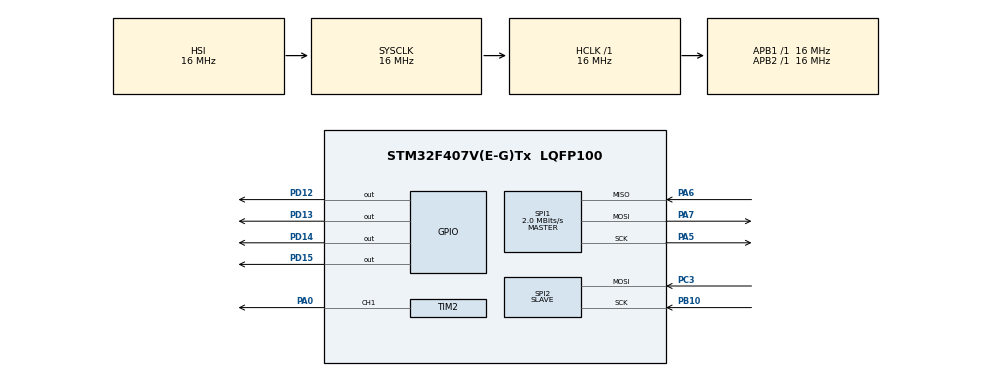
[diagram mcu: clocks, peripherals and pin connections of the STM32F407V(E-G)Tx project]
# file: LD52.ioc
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Mcu.Family=STM32F4
Mcu.Name=STM32F407V(E-G)Tx
Mcu.Package=LQFP100
NVIC.PriorityGroup=NVIC_PRIORITYGROUP_4
NVIC.SPI2_IRQn=true\:0\:0\:false\:false\:true\:true\:true\:true
NVIC.TIM2_IRQn=true\:0\:0\:false\:false\:true\:true\:true\:true
PA0-WKUP.Signal=S_TIM2_CH1_ETR
PA13.Mode=Trace_Asynchronous_SW
PA13.Signal=SYS_JTMS-SWDIO
PA14.Mode=Trace_Asynchronous_SW
PA14.Signal=SYS_JTCK-SWCLK
PA5.Mode=Full_Duplex_Master
PA5.Signal=SPI1_SCK
PA6.Mode=Full_Duplex_Master
PA6.Signal=SPI1_MISO
PA7.Mode=Full_Duplex_Master
PA7.Signal=SPI1_MOSI
PB10.Mode=RX_Only_Simplex_Unidirect_Slave
PB10.Signal=SPI2_SCK
PB3.Mode=Trace_Asynchronous_SW
PB3.Signal=SYS_JTDO-SWO
PC2.Signal=SPI2_MISO
PC3.Mode=RX_Only_Simplex_Unidirect_Slave
PC3.Signal=SPI2_MOSI
PD12.Signal=GPIO_Output
PD13.Signal=GPIO_Output
PD14.Signal=GPIO_Output
PD15.Signal=GPIO_Output
ProjectManager.HeapSize=0x200
ProjectManager.StackSize=0x400
ProjectManager.TargetToolchain=STM32CubeIDE
RCC.AHBFreq_Value=16000000
RCC.APB1Freq_Value=16000000
RCC.APB2Freq_Value=16000000
RCC.CortexFreq_Value=16000000
RCC.HSE_VALUE=25000000
RCC.HSI_VALUE=16000000
RCC.LSE_VALUE=32768
RCC.SYSCLKFreq_VALUE=16000000
RCC.VCOOutputFreq_Value=192000000
SH.S_TIM2_CH1_ETR.0=TIM2_CH1,PWM Generation1 CH1
SPI1.BaudRatePrescaler=SPI_BAUDRATEPRESCALER_8
SPI1.CalculateBaudRate=2.0 MBits/s
SPI1.Direction=SPI_DIRECTION_2LINES
SPI1.Mode=SPI_MODE_MASTER
SPI1.VirtualType=VM_MASTER
SPI2.Direction=SPI_DIRECTION_2LINES_RXONLY
SPI2.Mode=SPI_MODE_SLAVE
SPI2.VirtualType=VM_SLAVE
TIM2.Channel-PWM\ Generation1\ CH1=TIM_CHANNEL_1
TIM2.Period=1000-1
TIM2.Prescaler=16000-1
TIM2.Pulse-PWM\ Generation1\ CH1=1000-1
VP_TIM2_VS_ClockSourceINT.Mode=Internal
board=custom

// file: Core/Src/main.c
/* USER CODE BEGIN Header */
/**
  ******************************************************************************
  * @file           : main.c
  * @brief          : Main program body
  ******************************************************************************
  * @attention
  *
  * Copyright (c) 2024 STMicroelectronics.
  * All rights reserved.
  *
  * This software is licensed under terms that can be found in the LICENSE file
  * in the root directory of this software component.
  * If no LICENSE file comes with this software, it is provided AS-IS.
  *
  ******************************************************************************
  */
/* USER CODE END Header */
#include "main.h"

/* USER CODE BEGIN Includes */
#include "stm32f4xx_hal.h"
/* USER CODE END Includes */

SPI_HandleTypeDef hspi1;
SPI_HandleTypeDef hspi2;

TIM_HandleTypeDef htim2;

void SystemClock_Config(void);
static void MX_GPIO_Init(void);
static void MX_SPI1_Init(void);
static void MX_SPI2_Init(void);
static void MX_TIM2_Init(void);

int main(void)
{

  /* MCU Configuration--------------------------------------------------------*/

  /* Reset of all peripherals, Initializes the Flash interface and the Systick. */
  HAL_Init();

  /* Configure the system clock */
  SystemClock_Config();

  /* Initialize all configured peripherals */
  MX_GPIO_Init();
  MX_SPI1_Init();
  MX_SPI2_Init();
  MX_TIM2_Init();
  /* USER CODE BEGIN 2 */
  HAL_TIM_PWM_Start(&htim2, TIM_CHANNEL_1);

  HAL_TIM_Base_Init(&htim2);
  HAL_TIM_Base_Start_IT(&htim2);

  /* USER CODE END TIM2_IRQn 0 */
  HAL_TIM_IRQHandler(&htim2);
  /* USER CODE BEGIN TIM2_IRQn 1 */
  HAL_GPIO_TogglePin(GPIOD, GPIO_PIN_15);

  Start_SPI2_Receive();
  uint8_t dataToSend[] = {4, 5, 6, 7};
  uint8_t index = 0;

  /* USER CODE END 2 */

  /* Infinite loop */
  /* USER CODE BEGIN WHILE */
  while (1)
  {
  HAL_SPI_Transmit(&hspi1, &dataToSend[index], 1, 100);  // Transmit data
  index = (index + 1) % 4;  // Rotate through the array

    /* USER CODE END WHILE */

  }
}

void SystemClock_Config(void)
{
  RCC_OscInitTypeDef RCC_OscInitStruct = {0};
  RCC_ClkInitTypeDef RCC_ClkInitStruct = {0};

  /** Configure the main internal regulator output voltage
  */
  __HAL_RCC_PWR_CLK_ENABLE();
  __HAL_PWR_VOLTAGESCALING_CONFIG(PWR_REGULATOR_VOLTAGE_SCALE1);

  /** Initializes the RCC Oscillators according to the specified parameters
  * in the RCC_OscInitTypeDef structure.
  */
  RCC_OscInitStruct.OscillatorType = RCC_OSCILLATORTYPE_HSI;
  RCC_OscInitStruct.HSIState = RCC_HSI_ON;
  RCC_OscInitStruct.HSICalibrationValue = RCC_HSICALIBRATION_DEFAULT;
  RCC_OscInitStruct.PLL.PLLState = RCC_PLL_NONE;
  if (HAL_RCC_OscConfig(&RCC_OscInitStruct) != HAL_OK)
  {
    Error_Handler();
  }

  /** Initializes the CPU, AHB and APB buses clocks
  */
  RCC_ClkInitStruct.ClockType = RCC_CLOCKTYPE_HCLK|RCC_CLOCKTYPE_SYSCLK
                              |RCC_CLOCKTYPE_PCLK1|RCC_CLOCKTYPE_PCLK2;
  RCC_ClkInitStruct.SYSCLKSource = RCC_SYSCLKSOURCE_HSI;
  RCC_ClkInitStruct.AHBCLKDivider = RCC_SYSCLK_DIV1;
  RCC_ClkInitStruct.APB1CLKDivider = RCC_HCLK_DIV1;
  RCC_ClkInitStruct.APB2CLKDivider = RCC_HCLK_DIV1;

  if (HAL_RCC_ClockConfig(&RCC_ClkInitStruct, FLASH_LATENCY_0) != HAL_OK)
  {
    Error_Handler();
  }
}

static void MX_SPI1_Init(void)
{

  /* SPI1 parameter configuration*/
  hspi1.Instance = SPI1;
  hspi1.Init.Mode = SPI_MODE_MASTER;
  hspi1.Init.Direction = SPI_DIRECTION_2LINES;
  hspi1.Init.DataSize = SPI_DATASIZE_8BIT;
  hspi1.Init.CLKPolarity = SPI_POLARITY_LOW;
  hspi1.Init.CLKPhase = SPI_PHASE_1EDGE;
  hspi1.Init.NSS = SPI_NSS_SOFT;
  hspi1.Init.BaudRatePrescaler = SPI_BAUDRATEPRESCALER_8;
  hspi1.Init.FirstBit = SPI_FIRSTBIT_MSB;
  hspi1.Init.TIMode = SPI_TIMODE_DISABLE;
  hspi1.Init.CRCCalculation = SPI_CRCCALCULATION_DISABLE;
  hspi1.Init.CRCPolynomial = 10;
  if (HAL_SPI_Init(&hspi1) != HAL_OK)
  {
    Error_Handler();
  }

}

static void MX_SPI2_Init(void)
{

  /* SPI2 parameter configuration*/
  hspi2.Instance = SPI2;
  hspi2.Init.Mode = SPI_MODE_SLAVE;
  hspi2.Init.Direction = SPI_DIRECTION_2LINES;
  hspi2.Init.DataSize = SPI_DATASIZE_8BIT;
  hspi2.Init.CLKPolarity = SPI_POLARITY_LOW;
  hspi2.Init.CLKPhase = SPI_PHASE_1EDGE;
  hspi2.Init.NSS = SPI_NSS_SOFT;
  hspi2.Init.FirstBit = SPI_FIRSTBIT_MSB;
  hspi2.Init.TIMode = SPI_TIMODE_DISABLE;
  hspi2.Init.CRCCalculation = SPI_CRCCALCULATION_DISABLE;
  hspi2.Init.CRCPolynomial = 10;
  if (HAL_SPI_Init(&hspi2) != HAL_OK)
  {
    Error_Handler();
  }

}

static void MX_TIM2_Init(void)
{

  TIM_ClockConfigTypeDef sClockSourceConfig = {0};
  TIM_MasterConfigTypeDef sMasterConfig = {0};
  TIM_OC_InitTypeDef sConfigOC = {0};

  htim2.Instance = TIM2;
  htim2.Init.Prescaler = 16000-1;
  htim2.Init.CounterMode = TIM_COUNTERMODE_UP;
  htim2.Init.Period = 1000-1;
  htim2.Init.ClockDivision = TIM_CLOCKDIVISION_DIV1;
  htim2.Init.AutoReloadPreload = TIM_AUTORELOAD_PRELOAD_DISABLE;
  if (HAL_TIM_Base_Init(&htim2) != HAL_OK)
  {
    Error_Handler();
  }
  sClockSourceConfig.ClockSource = TIM_CLOCKSOURCE_INTERNAL;
  if (HAL_TIM_ConfigClockSource(&htim2, &sClockSourceConfig) != HAL_OK)
  {
    Error_Handler();
  }
  if (HAL_TIM_PWM_Init(&htim2) != HAL_OK)
  {
    Error_Handler();
  }
  sMasterConfig.MasterOutputTrigger = TIM_TRGO_RESET;
  sMasterConfig.MasterSlaveMode = TIM_MASTERSLAVEMODE_DISABLE;
  if (HAL_TIMEx_MasterConfigSynchronization(&htim2, &sMasterConfig) != HAL_OK)
  {
    Error_Handler();
  }
  sConfigOC.OCMode = TIM_OCMODE_PWM1;
  sConfigOC.Pulse = 1000-1;
  sConfigOC.OCPolarity = TIM_OCPOLARITY_HIGH;
  sConfigOC.OCFastMode = TIM_OCFAST_DISABLE;
  if (HAL_TIM_PWM_ConfigChannel(&htim2, &sConfigOC, TIM_CHANNEL_1) != HAL_OK)
  {
    Error_Handler();
  }
  HAL_TIM_MspPostInit(&htim2);

}

void HAL_TIM_PeriodElapsedCallback(TIM_HandleTypeDef *htim) {

  }
static void MX_GPIO_Init(void)
{
  GPIO_InitTypeDef GPIO_InitStruct = {0};

  /* GPIO Ports Clock Enable */
  __HAL_RCC_GPIOC_CLK_ENABLE();
  __HAL_RCC_GPIOA_CLK_ENABLE();
  __HAL_RCC_GPIOB_CLK_ENABLE();
  __HAL_RCC_GPIOD_CLK_ENABLE();

  /*Configure GPIO pin Output Level */
  HAL_GPIO_WritePin(GPIOD, GPIO_PIN_12|GPIO_PIN_13|GPIO_PIN_14|GPIO_PIN_15, GPIO_PIN_RESET);

  /*Configure GPIO pins : PD12 PD13 PD14 PD15 */
  GPIO_InitStruct.Pin = GPIO_PIN_12|GPIO_PIN_13|GPIO_PIN_14|GPIO_PIN_15;
  GPIO_InitStruct.Mode = GPIO_MODE_OUTPUT_PP;
  GPIO_InitStruct.Pull = GPIO_NOPULL;
  GPIO_InitStruct.Speed = GPIO_SPEED_FREQ_LOW;
  HAL_GPIO_Init(GPIOD, &GPIO_InitStruct);

}

void Error_Handler(void)
{
  __disable_irq();
  while (1)
  {
  }
}
